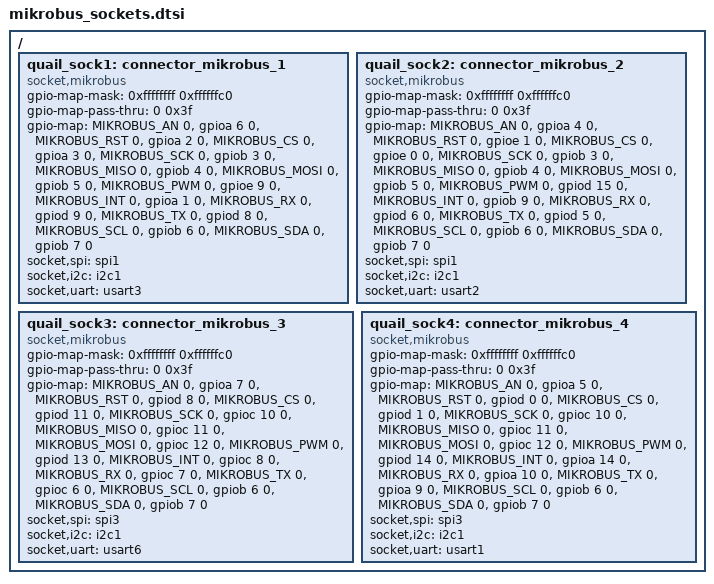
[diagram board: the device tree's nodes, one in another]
/*
 * Board-DT fragment: MikroE Quail typed mikroBUS socket nodes (rigs
 * Convention 4 — typed sockets live in the board's own devicetree).
 *
 * Layered on top of the REAL upstream mikroe_quail.dts by the `rig` board
 * EXTENSION variant (board.yml `extend:`) -- included from
 * mikroe_quail_stm32f427xx_rig.dts, alongside the base board's own legacy
 * mikrobus_N_header / edge_header connector nexuses (unmodified, they come
 * along for free via the base include -- harmless duplication, not
 * referenced by these sockets). socket,spi/i2c/uart point at the real
 * controllers (&spi1/&spi3/&i2c1/&usart*) directly, so no legacy alias is
 * needed.
 *
 * Content identical to the board clone's own mikrobus_sockets.dtsi --
 * copied in here so the extension has no long-term dependency on the
 * clone (deleted in full, slice E4, board-extension-migration.md).
 *
 * gpio-map child pins use the MIKROBUS_* indices from
 * <dt-bindings/connector/mikrobus.h> (btr-shields' own header — no upstream
 * equivalent exists for mikroBUS, unlike the Arduino R3 case). Full 12
 * positions per socket, mirroring the legacy mikrobus_N_header maps 1:1
 * (same pins), so any shield position claim (not just CS/RST) resolves to a
 * real SoC pin.
 *
 * Labels quail_sock1..quail_sock4 match the scenario rigs (S5/S4b).
 *
 * SPDX-License-Identifier: Apache-2.0
 */

#include <dt-bindings/connector/mikrobus.h>

/ {
	quail_sock1: connector_mikrobus_1 {
		compatible = "socket,mikrobus";
		#gpio-cells = <2>;
		gpio-map-mask = <0xffffffff 0xffffffc0>;
		gpio-map-pass-thru = <0 0x3f>;
		gpio-map = <MIKROBUS_AN   0 &gpioa 6  0>,
			   <MIKROBUS_RST  0 &gpioa 2  0>,
			   <MIKROBUS_CS   0 &gpioa 3  0>,
			   <MIKROBUS_SCK  0 &gpiob 3  0>,
			   <MIKROBUS_MISO 0 &gpiob 4  0>,
			   <MIKROBUS_MOSI 0 &gpiob 5  0>,
			   <MIKROBUS_PWM  0 &gpioe 9  0>,
			   <MIKROBUS_INT  0 &gpioa 1  0>,
			   <MIKROBUS_RX   0 &gpiod 9  0>,
			   <MIKROBUS_TX   0 &gpiod 8  0>,
			   <MIKROBUS_SCL  0 &gpiob 6  0>,
			   <MIKROBUS_SDA  0 &gpiob 7  0>;
		socket,spi = <&spi1>;
		socket,i2c = <&i2c1>;
		socket,uart = <&usart3>;
	};

	quail_sock2: connector_mikrobus_2 {
		compatible = "socket,mikrobus";
		#gpio-cells = <2>;
		gpio-map-mask = <0xffffffff 0xffffffc0>;
		gpio-map-pass-thru = <0 0x3f>;
		gpio-map = <MIKROBUS_AN   0 &gpioa 4  0>,
			   <MIKROBUS_RST  0 &gpioe 1  0>,
			   <MIKROBUS_CS   0 &gpioe 0  0>,
			   <MIKROBUS_SCK  0 &gpiob 3  0>,
			   <MIKROBUS_MISO 0 &gpiob 4  0>,
			   <MIKROBUS_MOSI 0 &gpiob 5  0>,
			   <MIKROBUS_PWM  0 &gpiod 15 0>,
			   <MIKROBUS_INT  0 &gpiob 9  0>,
			   <MIKROBUS_RX   0 &gpiod 6  0>,
			   <MIKROBUS_TX   0 &gpiod 5  0>,
			   <MIKROBUS_SCL  0 &gpiob 6  0>,
			   <MIKROBUS_SDA  0 &gpiob 7  0>;
		socket,spi = <&spi1>;
		socket,i2c = <&i2c1>;
		socket,uart = <&usart2>;
	};

	quail_sock3: connector_mikrobus_3 {
		compatible = "socket,mikrobus";
		#gpio-cells = <2>;
		gpio-map-mask = <0xffffffff 0xffffffc0>;
		gpio-map-pass-thru = <0 0x3f>;
		gpio-map = <MIKROBUS_AN   0 &gpioa 7  0>,
			   <MIKROBUS_RST  0 &gpiod 8  0>,
			   <MIKROBUS_CS   0 &gpiod 11 0>,
			   <MIKROBUS_SCK  0 &gpioc 10 0>,
			   <MIKROBUS_MISO 0 &gpioc 11 0>,
			   <MIKROBUS_MOSI 0 &gpioc 12 0>,
			   <MIKROBUS_PWM  0 &gpiod 13 0>,
			   <MIKROBUS_INT  0 &gpioc 8  0>,
			   <MIKROBUS_RX   0 &gpioc 7  0>,
			   <MIKROBUS_TX   0 &gpioc 6  0>,
			   <MIKROBUS_SCL  0 &gpiob 6  0>,
			   <MIKROBUS_SDA  0 &gpiob 7  0>;
		socket,spi = <&spi3>;
		socket,i2c = <&i2c1>;
		socket,uart = <&usart6>;
	};

	quail_sock4: connector_mikrobus_4 {
		compatible = "socket,mikrobus";
		#gpio-cells = <2>;
		gpio-map-mask = <0xffffffff 0xffffffc0>;
		gpio-map-pass-thru = <0 0x3f>;
		gpio-map = <MIKROBUS_AN   0 &gpioa 5  0>,
			   <MIKROBUS_RST  0 &gpiod 0  0>,
			   <MIKROBUS_CS   0 &gpiod 1  0>,
			   <MIKROBUS_SCK  0 &gpioc 10 0>,
			   <MIKROBUS_MISO 0 &gpioc 11 0>,
			   <MIKROBUS_MOSI 0 &gpioc 12 0>,
			   <MIKROBUS_PWM  0 &gpiod 14 0>,
			   <MIKROBUS_INT  0 &gpioa 14 0>,
			   <MIKROBUS_RX   0 &gpioa 10 0>,
			   <MIKROBUS_TX   0 &gpioa 9  0>,
			   <MIKROBUS_SCL  0 &gpiob 6  0>,
			   <MIKROBUS_SDA  0 &gpiob 7  0>;
		socket,spi = <&spi3>;
		socket,i2c = <&i2c1>;
		socket,uart = <&usart1>;
	};
};
